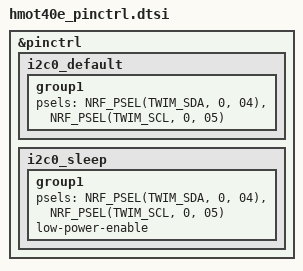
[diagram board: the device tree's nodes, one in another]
&pinctrl {    
    i2c0_default: i2c0_default {
        group1 {
            psels = <NRF_PSEL(TWIM_SDA, 0, 04)>, // D2->D4 P0.04に変えるかも
                    <NRF_PSEL(TWIM_SCL, 0, 05)>; // D3->D5 P0.05に変えるかも
            //bias-pull-up;
        };
    };
      
    i2c0_sleep: i2c0_sleep {
        group1 {
            psels = <NRF_PSEL(TWIM_SDA, 0, 04)>,
                    <NRF_PSEL(TWIM_SCL, 0, 05)>;
            low-power-enable;
        };
    };
};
